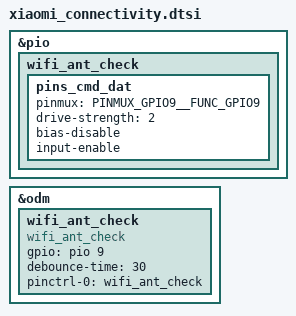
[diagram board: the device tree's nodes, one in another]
&pio {
	wifi_ant_check: wifi_ant_check {
		pins_cmd_dat {
			pinmux = <PINMUX_GPIO9__FUNC_GPIO9>;
			drive-strength = <2>;
			bias-disable;
			input-enable;
		};
	};
};

&odm {
	wifi_ant_check {
		compatible = "wifi_ant_check";
		gpio = <&pio 9 0>;
		debounce-time = <30>;
		pinctrl-names = "default";
		pinctrl-0 = <&wifi_ant_check>;
	};
};
